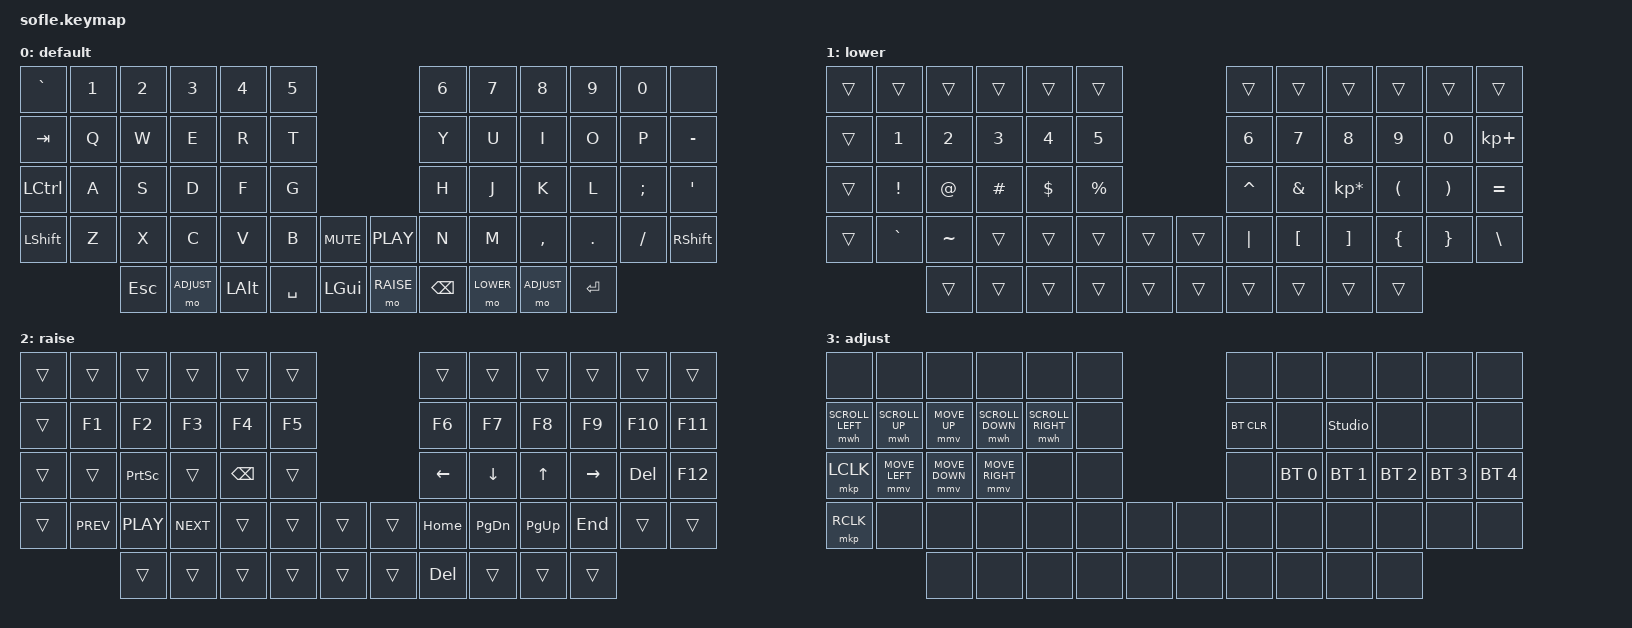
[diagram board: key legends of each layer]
/*
 * Copyright (c) 2020 The ZMK Contributors
 *
 * SPDX-License-Identifier: MIT
 */

#include <behaviors.dtsi>
#include <dt-bindings/zmk/keys.h>
#include <dt-bindings/zmk/bt.h>
#include <dt-bindings/zmk/rgb.h>
#include <dt-bindings/zmk/ext_power.h>
#include <dt-bindings/zmk/mouse.h>

#define BASE 0
#define LOWER 1
#define RAISE 2
#define ADJUST 3
#define MOUSE 4

/* Copied from https://gist.github.com/krissen/dd27082e7ab0575619c7a31f4d2ec7ae#file-zmk_mouse_support-md */

#define U_MOUSE_MOVE_MAX 2000                     /* <--- New max speed setting (default: 600) */
#undef MOVE_UP
#undef MOVE_DOWN
#undef MOVE_LEFT
#undef MOVE_RIGHT
#define MOVE_UP MOVE_VERT(-U_MOUSE_MOVE_MAX)
#define MOVE_DOWN MOVE_VERT(U_MOUSE_MOVE_MAX)
#define MOVE_LEFT MOVE_HOR(-U_MOUSE_MOVE_MAX)
#define MOVE_RIGHT MOVE_HOR(U_MOUSE_MOVE_MAX)

&mmv {
	time-to-max-speed-ms = <800>;             /* <--- How long time until max speed is reached (default: 500) */
};

#define U_MOUSE_SCROLL_MAX 25                    /* <--- New max speed setting (default: 10) */

#undef SCROLL_UP
#undef SCROLL_DOWN
#undef SCROLL_LEFT
#undef SCROLL_RIGHT
#define SCROLL_UP SCROLL_VERT(U_MOUSE_SCROLL_MAX)
#define SCROLL_DOWN SCROLL_VERT(-U_MOUSE_SCROLL_MAX)
#define SCROLL_LEFT SCROLL_HOR(-U_MOUSE_SCROLL_MAX)
#define SCROLL_RIGHT SCROLL_HOR(U_MOUSE_SCROLL_MAX)

&mwh {
  time-to-max-speed-ms = <1000>;                 /* <--- How long time until max speed is reached */
};


/ {
    keymap {
        compatible = "zmk,keymap";

        default_layer {
            label = "default";
// ----------------------------------------------------------------------------------------------------------------
// |   `   |  1  |  2  |  3  |  4   |   5   |                   |   6  |   7   |    8    |   9   |   0   |       |
// |  TAB  |  Q  |  W  |  E  |  R   |   T   |                   |   Y  |   U   |    I    |   O   |   P   | MINUS |
// |  CTRL |  A  |  S  |  D  |  F   |   G   |                   |   H  |   J   |    K    |   L   |   ;   |   '   |
// | SHIFT |  Z  |  X  |  C  |  V   |   B   |  MUTE  |  | PLAY  |   N  |   M   |    ,    |   .   |   /   | SHIFT |
//               | ESC | ADJ | LALT | SPACE |  LGUI  |  | RAISE | BSPC | LOWER | ADJUST  | ENTER |
            bindings = <
&kp GRAVE &kp N1 &kp N2   &kp N3      &kp N4    &kp N5                            &kp N6        &kp N7    &kp N8         &kp N9   &kp N0   &none
&kp TAB   &kp Q  &kp W    &kp E       &kp R     &kp T                             &kp Y         &kp U     &kp I          &kp O    &kp P    &kp MINUS
&kp LCTRL &kp A  &kp S    &kp D       &kp F     &kp G                             &kp H         &kp J     &kp K          &kp L    &kp SEMI &kp SQT
&kp LSHFT &kp Z  &kp X    &kp C       &kp V     &kp B      &kp C_MUTE  &kp C_PLAY &kp N         &kp M     &kp COMMA      &kp DOT  &kp FSLH &kp RSHFT
                 &kp ESC  &mo ADJUST  &kp LALT  &kp SPACE  &kp LGUI    &mo RAISE  &kp BSPC      &mo LOWER &mo ADJUST     &kp RET
            >;

            sensor-bindings = <&inc_dec_kp C_VOL_UP C_VOL_DN &inc_dec_kp C_VOL_UP C_VOL_DN>;
        };

        lower_layer {
            label = "lower";
// TODO: Some binds are waiting for shifted keycode support.
// ------------------------------------------------------------------------------------------------------------
// |       |     |     |      |      |      |                   |      |       |       |      |       |       |
// |       |  1  |  2  |  3   |  4   |  5   |                   |  6   |  7    |  8    |  9   |   0   |   +   |
// |       |  !  |  @  |  #   |  $   |  %   |                   |  ^   |  &    |  *    |  (   |   )   |   =   |
// |       |  `  |  ~  |      |      |      |        |  |       |  |   |  [    |  ]    |  {   |   }   |   \   |
//               |     |      |      |      |        |  |       |      |       |       |      |
            bindings = <
&trans    &trans    &trans    &trans      &trans    &trans                    &trans    &trans   &trans          &trans    &trans    &trans
&trans    &kp N1    &kp N2    &kp N3      &kp N4    &kp N5                    &kp N6    &kp N7   &kp N8          &kp N9    &kp N0    &kp KP_PLUS
&trans    &kp EXCL  &kp AT    &kp HASH    &kp DLLR  &kp PRCNT                 &kp CARET &kp AMPS &kp KP_MULTIPLY &kp LPAR  &kp RPAR  &kp EQUAL
&trans    &kp GRAVE &kp TILDE &trans      &trans    &trans     &trans &trans  &kp PIPE  &kp LBKT &kp RBKT        &kp LBRC  &kp RBRC  &kp BACKSLASH
                    &trans    &trans      &trans    &trans     &trans &trans  &trans    &trans   &trans          &trans
            >;

            sensor-bindings = <&inc_dec_kp C_AC_SCROLL_DOWN C_AC_SCROLL_UP &inc_dec_kp C_BRIGHTNESS_INC C_BRIGHTNESS_DEC>;
        };

        raise_layer {
            label = "raise";
// ------------------------------------------------------------------------------------------------------------
// |       |        |        |        |       |      |                |      |      |       |      |       |       |
// |       |   F1   |  F2    |   F3   |  F4   | F5   |                |  F6  |  F7  |  F8   |  F9  |  F10  |  F11  |
// |       |        | PRINT  |        | BSPC  |      |                |  <-  |   v  |   ^   |  ->  |       |  F12  |
// |       | C_PREV | C_PLAY | C_NEXT |       |      |      |  |      | HOME | PG_DN| PG_UP | END  |       |       |
//                  |        |        |       |      |      |  |      | DEL  |      |       |      |
            bindings = <
&trans     &trans       &trans           &trans       &trans       &trans                   &trans    &trans    &trans     &trans    &trans  &trans
&trans     &kp F1       &kp F2           &kp F3       &kp F4       &kp F5                   &kp F6    &kp F7    &kp F8     &kp F9    &kp F10 &kp F11
&trans     &trans       &kp PRINTSCREEN  &trans       &kp BSPC     &trans                   &kp LEFT  &kp DOWN  &kp UP     &kp RIGHT &kp DEL &kp F12
&trans     &kp C_PREV   &kp C_PLAY       &kp C_NEXT   &trans       &trans   &trans  &trans  &kp HOME  &kp PG_DN &kp PG_UP  &kp END   &trans  &trans
                        &trans           &trans       &trans       &trans   &trans  &trans  &kp DEL   &trans    &trans     &trans
            >;

            sensor-bindings = <&inc_dec_kp C_AC_SCROLL_DOWN C_AC_SCROLL_UP &inc_dec_kp C_REWIND C_FAST_FORWARD>;
        };

        adjust_layer {
            label = "adjust";
            bindings = <
&none             &none           &none           &none            &none              &none                                  &none         &none          &none          &none          &none          &none
&mwh SCROLL_LEFT  &mwh SCROLL_UP  &mmv MOVE_UP    &mwh SCROLL_DOWN &mwh SCROLL_RIGHT  &none                                  &bt BT_CLR    &none          &studio_unlock &none          &none          &none
&mkp LCLK         &mmv MOVE_LEFT  &mmv MOVE_DOWN  &mmv MOVE_RIGHT  &none              &none                                  &none         &bt BT_SEL 0   &bt BT_SEL 1   &bt BT_SEL 2   &bt BT_SEL 3   &bt BT_SEL 4
&mkp RCLK         &none           &none           &none            &none              &none            &none  &none          &none         &none          &none          &none          &none          &none
                                  &none           &none            &none              &none            &none  &none          &none         &none          &none          &none
            >;
        };

    };
};
